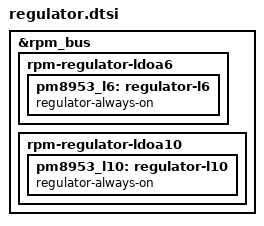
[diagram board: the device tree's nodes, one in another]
&rpm_bus {
	rpm-regulator-ldoa6 {
		pm8953_l6: regulator-l6 {
            regulator-always-on;
		};
	};

	rpm-regulator-ldoa10 {
		pm8953_l10: regulator-l10 {
            regulator-always-on;
		};
	};
};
